# CY8C3246PVI_147 register map
File version: 0.1
Registers are 8-bit, read-write, no defined reset value unless marked. A register's access mark holds for its fields unless they carry their own. Offsets are from the block's base; [hi:lo] are bit positions; 'fields as' and 'values as' point back to an identical list.

## RESET_FF
Base 0x00000000
0x6574 RESET_FF_CONTROL_REG

## FF_STATUS
Base 0x00000000
0x6564 FF_STATUS_STATUS_REG
0x6584 FF_STATUS_MASK_REG
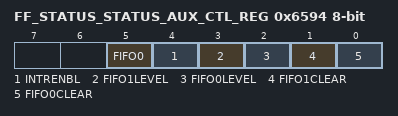
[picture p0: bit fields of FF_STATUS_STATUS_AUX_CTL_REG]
0x6594 FF_STATUS_STATUS_AUX_CTL_REG
  [5] FIFO0 — FIFO0 clear
    1=ENABLED (Enable counter); 0=DISABLED (Disable counter)
  [4] INTRENBL — Enables or disables the Interrupt
    1=ENABLED (Interrupt enabled); 0=DISABLED (Interrupt disabled)
  [3] FIFO1LEVEL — FIFO level
    1=ENABLED (FIFO LVL: input mode: FIFO at least 1/2 empty; output mode: FIFO at least 1/2 full); 0=DISABLED (FIFO LVL: input mode: FIFO not full; output mode: FIFO not empty)
  [2] FIFO0LEVEL — FIFO level
    values as FIFO1LEVEL
  [1] FIFO1CLEAR — FIFO clear
    1=ENABLED (Clear FIFO state); 0=DISABLED (Normal FIFO operation)
  [0] FIFO0CLEAR — FIFO clear
    values as FIFO1CLEAR

## RS485_CTS
Base 0x00000000
0x647B RS485_CTS_CONTROL_REG

## MOTOR_ON_OFF
Base 0x00000000
0x647C MOTOR_ON_OFF_CONTROL_REG

## WATCHDOG_REFRESH
Base 0x00000000
0x6579 WATCHDOG_REFRESH_CONTROL_REG

## WATCHDOG_COUNTER
Base 0x00000000
0x43A3 WATCHDOG_COUNTER_GLOBAL_ENABLE — PM.ACT.CFG
  [3:0] en_timer — Enable timer/counters.
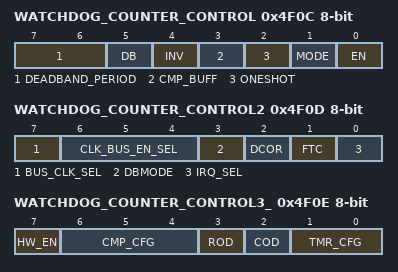
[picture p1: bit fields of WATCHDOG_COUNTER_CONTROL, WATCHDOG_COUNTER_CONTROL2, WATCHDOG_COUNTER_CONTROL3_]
0x4F0C WATCHDOG_COUNTER_CONTROL — TMRx.CFG0
  [7:6] DEADBAND_PERIOD
  [5] DB — Deadband mode--Deadband phases phi1 and phi2 are outputted on CMP and TC output pins respectively.
    0=Timer (CMP and TC are output.); 1=Deadband (PHI1 (instead of CMP) and PHI2 (instead of TC) are output.)
  [4] INV — Invert sense of TIMEREN signal
  [3] CMP_BUFF — Buffer compare register. Compare register updates only on timer terminal count.
  [2] ONESHOT — Timer stops upon reaching stop condition defined by TMR_CFG bits. Can be restarted by asserting TIMER RESET or disabling and re-enabling block.
  [1] MODE — Mode. (0 = Timer; 1 = Comparator)
    0=Timer mode. CNT/CMP register holds timer count value.; 1=Comparator mode. CNT/CMP register holds comparator threshold value.
  [0] EN — Enables timer/comparator.
0x4F0D WATCHDOG_COUNTER_CONTROL2 — TMRx.CFG1
  [7] BUS_CLK_SEL — Bus Clock selection.
  [6:4] CLK_BUS_EN_SEL — Digital Global Clock selection.
  [3] DBMODE — Deadband mode (asynchronous/synchronous). CMP output pin is also affected when not in deadband mode (CFG0.DEADBAND).
  [2] DCOR — Disable Clear on Read (DCOR) of Status Register SR0.
  [1] FTC — First Terminal Count (FTC). Setting this bit forces a single pulse on the TC pin when first enabled.
    0=Disable_FTC (Disable the single cycle pulse, which signifies the timer is starting.); 1=Enable_FTC (Enable the single cycle pulse, which signifies the timer is starting.)
  [0] IRQ_SEL — Irq selection. (0 = raw interrupts; 1 = status register interrupts)
0x4F0E WATCHDOG_COUNTER_CONTROL3_ — TMRx.CFG2
  [7] HW_EN — When set Timer Enable controls counting.
  [6:4] CMP_CFG — Comparator configurations
    0=Equal (Compare Equal); 1=Less_than (Compare Less Than); 2=Less_than_or_equal (Compare Less Than or Equal .); 3=Greater (Compare Greater Than .); 4=Greater_than_or_equal (Compare Greater Than or Equal)
  [3] ROD — Reset On Disable (ROD). Resets internal state of output logic
  [2] COD — Clear On Disable (COD). Clears or gates outputs to zero.
  [1:0] TMR_CFG — Timer configuration (MODE = 0): 000 = Continuous; 001 = Pulsewidth; 010 = Period; 011 = Stop on IRQ
    0=Continuous (Timer runs while EN bit of CFG0 register is set to '1'.); 1=Pulsewidth (Timer runs from positive to negative edge of TIMEREN.); 2=Period (Timer runs from positive to positive edge of TIMEREN.); 3=Irq (Timer runs until IRQ.)
0x4F10 WATCHDOG_COUNTER_PERIOD — TMRx.PER0 - Assigned Period
0x4F12 WATCHDOG_COUNTER_COUNTER — TMRx.CNT_CMP0 - Current Down Counter Value
